AUTOSAR XML (schema 00047)
package /ETAS_BIP
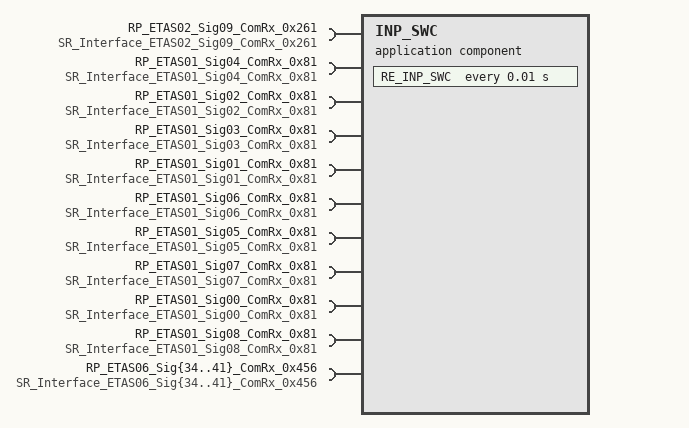
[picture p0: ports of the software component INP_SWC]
  application sw component type INP_SWC
    18 x require port:
      RP_ETAS02_Sig09_ComRx_0x261: required-interface=SR_Interface_ETAS02_Sig09_ComRx_0x261
      RP_ETAS01_Sig04_ComRx_0x81: required-interface=SR_Interface_ETAS01_Sig04_ComRx_0x81
      RP_ETAS01_Sig02_ComRx_0x81: required-interface=SR_Interface_ETAS01_Sig02_ComRx_0x81
      RP_ETAS01_Sig03_ComRx_0x81: required-interface=SR_Interface_ETAS01_Sig03_ComRx_0x81
      RP_ETAS01_Sig01_ComRx_0x81: required-interface=SR_Interface_ETAS01_Sig01_ComRx_0x81
      RP_ETAS01_Sig06_ComRx_0x81: required-interface=SR_Interface_ETAS01_Sig06_ComRx_0x81
      RP_ETAS01_Sig05_ComRx_0x81: required-interface=SR_Interface_ETAS01_Sig05_ComRx_0x81
      RP_ETAS01_Sig07_ComRx_0x81: required-interface=SR_Interface_ETAS01_Sig07_ComRx_0x81
      RP_ETAS01_Sig00_ComRx_0x81: required-interface=SR_Interface_ETAS01_Sig00_ComRx_0x81
      RP_ETAS01_Sig08_ComRx_0x81: required-interface=SR_Interface_ETAS01_Sig08_ComRx_0x81
      RP_ETAS06_Sig{34..41}_ComRx_0x456: required-interface=SR_Interface_ETAS06_Sig{34..41}_ComRx_0x456
    behavior IB_INP_SWC
      timing event TE_INP_SWC_10ms: start-on-event=RE_INP_SWC, period=0.01
      runnable RE_INP_SWC
        data-receive-point-by-arguments:
          18 x access:
            DRPA_ETAS01_Sig03_ComRx_0x81_0: accessed-variable=RP_ETAS01_Sig03_ComRx_0x81.ETAS01_Sig03_ComRx_0x81
            DRPA_ETAS01_Sig07_ComRx_0x81_0: accessed-variable=RP_ETAS01_Sig07_ComRx_0x81.ETAS01_Sig07_ComRx_0x81
            DRPA_ETAS01_Sig08_ComRx_0x81_0: accessed-variable=RP_ETAS01_Sig08_ComRx_0x81.ETAS01_Sig08_ComRx_0x81
            DRPA_ETAS01_Sig05_ComRx_0x81_0: accessed-variable=RP_ETAS01_Sig05_ComRx_0x81.ETAS01_Sig05_ComRx_0x81
            DRPA_ETAS01_Sig04_ComRx_0x81_0: accessed-variable=RP_ETAS01_Sig04_ComRx_0x81.ETAS01_Sig04_ComRx_0x81
            DRPA_ETAS01_Sig00_ComRx_0x81_0: accessed-variable=RP_ETAS01_Sig00_ComRx_0x81.ETAS01_Sig00_ComRx_0x81
            DRPA_ETAS01_Sig01_ComRx_0x81_0: accessed-variable=RP_ETAS01_Sig01_ComRx_0x81.ETAS01_Sig01_ComRx_0x81
            DRPA_ETAS01_Sig06_ComRx_0x81_0: accessed-variable=RP_ETAS01_Sig06_ComRx_0x81.ETAS01_Sig06_ComRx_0x81
            DRPA_ETAS01_Sig02_ComRx_0x81_0: accessed-variable=RP_ETAS01_Sig02_ComRx_0x81.ETAS01_Sig02_ComRx_0x81
            DRPA_ETAS01_Sig09_ComRx_0x261_0: accessed-variable=RP_ETAS02_Sig09_ComRx_0x261.ETAS02_Sig09_ComRx_0x261
            DRPA_ETAS06_Sig{34..41}_ComRx_0x456_0: accessed-variable=RP_ETAS06_Sig{34..41}_ComRx_0x456.ETAS06_Sig{34..41}_ComRx_0x456
